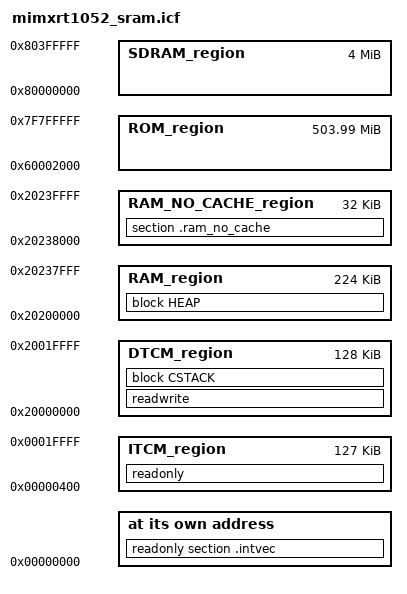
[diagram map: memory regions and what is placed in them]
/*###ICF### Section handled by ICF editor, don't touch! ****/
/*-Editor annotation file-*/
/* IcfEditorFile="$TOOLKIT_DIR$\config\ide\IcfEditor\cortex_v1_0.xml" */
/*-Specials-*/
define symbol __ICFEDIT_intvec_start__ = 0x00000000;
/*-Memory Regions-*/
define symbol __ICFEDIT_region_ROM_start__          = 0x60002000;
define symbol __ICFEDIT_region_ROM_end__            = 0x7F7FFFFF;
define symbol __ICFEDIT_region_RAM_start__          = 0x20200000;
define symbol __ICFEDIT_region_RAM_end__            = 0x20237FFF;
define symbol __ICFEDIT_region_RAM_NO_CACHE_start__ = 0x20238000;
define symbol __ICFEDIT_region_RAM_NO_CACHE_end__   = 0x2023FFFF;
define symbol __ICFEDIT_region_ITCM_start__         = 0x00000400;
define symbol __ICFEDIT_region_ITCM_end__           = 0x0001FFFF;
define symbol __ICFEDIT_region_DTCM_start__         = 0x20000000;
define symbol __ICFEDIT_region_DTCM_end__           = 0x2001FFFF;
define symbol __ICFEDIT_region_SDRAM_start__        = 0x80000000;
define symbol __ICFEDIT_region_SDRAM_end__          = 0x803FFFFF;
/*-Sizes-*/
define symbol __ICFEDIT_size_cstack__ = 0x400;
define symbol __ICFEDIT_size_heap__   = 0x30000;
/**** End of ICF editor section. ###ICF###*/

define memory mem with size  = 4G;
define region ROM_region          = mem:[from __ICFEDIT_region_ROM_start__          to __ICFEDIT_region_ROM_end__];
define region RAM_region          = mem:[from __ICFEDIT_region_RAM_start__          to __ICFEDIT_region_RAM_end__];
define region RAM_NO_CACHE_region = mem:[from __ICFEDIT_region_RAM_NO_CACHE_start__ to __ICFEDIT_region_RAM_NO_CACHE_end__];
define region ITCM_region         = mem:[from __ICFEDIT_region_ITCM_start__         to __ICFEDIT_region_ITCM_end__];
define region DTCM_region         = mem:[from __ICFEDIT_region_DTCM_start__         to __ICFEDIT_region_DTCM_end__];
define region SDRAM_region        = mem:[from __ICFEDIT_region_SDRAM_start__        to __ICFEDIT_region_SDRAM_end__];

define block CSTACK with alignment = 8, size = __ICFEDIT_size_cstack__   { };
define block HEAP   with alignment = 8, size = __ICFEDIT_size_heap__     { };

initialize by copy { readwrite };
do not initialize  { section .noinit };

place at address mem:__ICFEDIT_intvec_start__ { readonly section .intvec };

place in ITCM_region { readonly };
place in DTCM_region { readwrite, block CSTACK };
place in RAM_NO_CACHE_region { section .ram_no_cache };
place in RAM_region { block HEAP };
